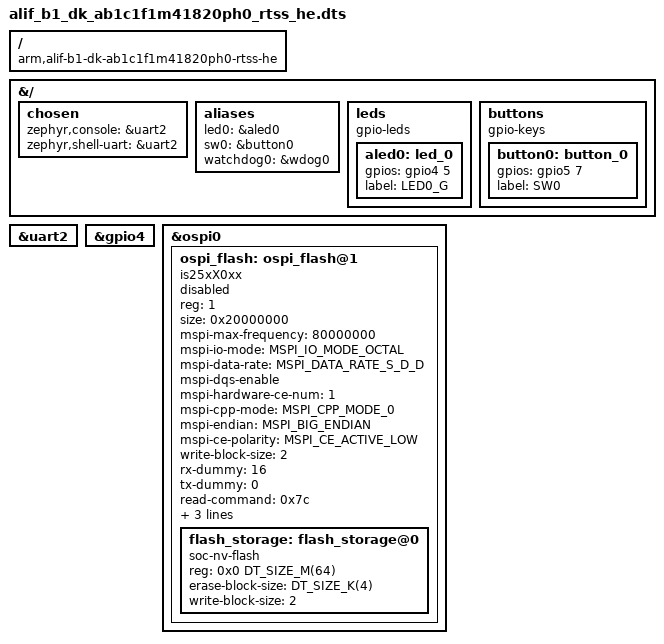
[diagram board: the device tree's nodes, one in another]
/* Copyright (c) 2025 Alif Semiconductor
 *
 * SPDX-License-Identifier: Apache-2.0
 */

/dts-v1/;

#include <alif/balletto/b1/ab1c1f1m41820ph0.dtsi>
#include "../common/balletto-pinctrl.dtsi"
#include "../common/balletto-sd-vsel.dtsi"

/ {
	compatible = "arm,alif-b1-dk-ab1c1f1m41820ph0-rtss-he";
	#address-cells = <1>;
	#size-cells = <1>;
};

&{/} {
	chosen {
		zephyr,console = &uart2;
		zephyr,shell-uart = &uart2;
	};

	aliases {
		led0 = &aled0;
		sw0 = &button0;
		watchdog0 = &wdog0;
	};

	leds {
		compatible = "gpio-leds";
		aled0: led_0 {
			gpios = <&gpio4 5 0>;
			label = "LED0_G";
		};
	};

	buttons {
		compatible = "gpio-keys";
		button0: button_0 {
			gpios = <&gpio5 7 0>;
			label = "SW0";
		};
	};
};

&uart2 {
	status = "okay";
};

&gpio4 {
	status = "okay";
};

&ospi0 {
	/* External Flash on OSPI */
	ospi_flash: ospi_flash@1 {
		compatible = "is25xX0xx";
		reg = <1>;
		size = <0x20000000>;
		mspi-max-frequency = <80000000>;
		mspi-io-mode = "MSPI_IO_MODE_OCTAL";
		mspi-data-rate = "MSPI_DATA_RATE_S_D_D";
		mspi-dqs-enable;
		mspi-hardware-ce-num = <1>;
		mspi-cpp-mode = "MSPI_CPP_MODE_0";
		mspi-endian = "MSPI_BIG_ENDIAN";
		mspi-ce-polarity = "MSPI_CE_ACTIVE_LOW";
		write-block-size = <2>;
		rx-dummy = <16>;
		tx-dummy = <0>;
		read-command = <0x7c>;
		write-command = <0x84>;
		command-length = "INSTR_1_BYTE";
		address-length = "ADDR_4_BYTE";

		/* Flash Size 64MB */
		#address-cells = <1>;
		#size-cells = <1>;

		flash_storage: flash_storage@0 {
			compatible = "soc-nv-flash";
			reg = <0x0 DT_SIZE_M(64)>;
			erase-block-size = <DT_SIZE_K(4)>;
			write-block-size = <2>;
		};
		status = "disabled";
	};
};
